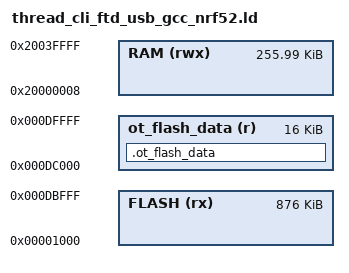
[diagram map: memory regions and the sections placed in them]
/* Linker script to configure memory regions. */

SEARCH_DIR(.)
GROUP(-lgcc -lc -lnosys)

MEMORY
{
  FLASH (rx) : ORIGIN = 0x1000, LENGTH = 0xdb000
  RAM (rwx) :  ORIGIN = 0x20000008, LENGTH = 0x3fff8
  ot_flash_data (r) : ORIGIN = 0xdc000, LENGTH = 0x4000
}

SECTIONS
{
  . = ALIGN(4);
  .ot_flash_data :
  {
    PROVIDE(__start_ot_flash_data = ORIGIN(ot_flash_data));
    KEEP(*(SORT(.ot_flash_data*)))
    PROVIDE(__stop_ot_flash_data = ORIGIN(ot_flash_data) + LENGTH(ot_flash_data));
  } > ot_flash_data
}

SECTIONS
{
  . = ALIGN(4);
  .mem_section_dummy_ram :
  {
  }
  .log_dynamic_data :
  {
    PROVIDE(__start_log_dynamic_data = .);
    KEEP(*(SORT(.log_dynamic_data*)))
    PROVIDE(__stop_log_dynamic_data = .);
  } > RAM
  .log_filter_data :
  {
    PROVIDE(__start_log_filter_data = .);
    KEEP(*(SORT(.log_filter_data*)))
    PROVIDE(__stop_log_filter_data = .);
  } > RAM

} INSERT AFTER .data;

SECTIONS
{
  .mem_section_dummy_rom :
  {
  }
  .pwr_mgmt_data :
  {
    PROVIDE(__start_pwr_mgmt_data = .);
    KEEP(*(SORT(.pwr_mgmt_data*)))
    PROVIDE(__stop_pwr_mgmt_data = .);
  } > FLASH
  .log_const_data :
  {
    PROVIDE(__start_log_const_data = .);
    KEEP(*(SORT(.log_const_data*)))
    PROVIDE(__stop_log_const_data = .);
  } > FLASH
  .log_backends :
  {
    PROVIDE(__start_log_backends = .);
    KEEP(*(SORT(.log_backends*)))
    PROVIDE(__stop_log_backends = .);
  } > FLASH
    .nrf_balloc :
  {
    PROVIDE(__start_nrf_balloc = .);
    KEEP(*(.nrf_balloc))
    PROVIDE(__stop_nrf_balloc = .);
  } > FLASH

} INSERT AFTER .text

ASSERT(__start_ot_flash_data > __etext, "Section ot_flash_data overlaps text section")

INCLUDE "nrf_common.ld"
